# ET6801 register map
Vendor: ETMCU Inc.; File version: v0.0.1
CPU: CM7 r2p1, little endian, MPU, FPU, I-cache, D-cache, ITCM, DTCM, 4 interrupt priority bits
Registers are 32-bit, read-write, reset 0x0 unless marked. A register's access mark holds for its fields unless they carry their own. Offsets are from the block's base; [hi:lo] are bit positions; {n}, {i} and the like mark numbered series.

## AES — Provide an overview of the purpose and functionality of the peripheral: aes_cfg
Base 0x40205000
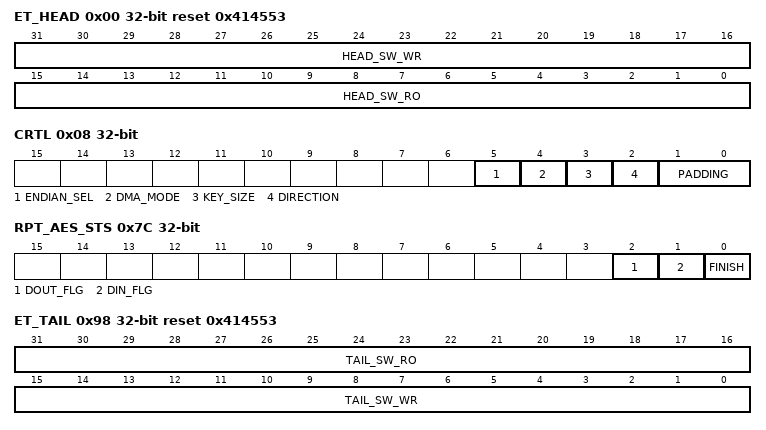
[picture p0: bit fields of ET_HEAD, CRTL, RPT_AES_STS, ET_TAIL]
0x00 ET_HEAD reset 0x414553
  [31:16] HEAD_SW_WR — 软件测试读写寄存器，硬件无访问
  [15:0] HEAD_SW_RO ro — 软件只读上报寄存器，硬件无访问,AES的ASICII 码表示
0x04 WORK
  [0] EN — AES模块使能控制信号。
0x08 CRTL
  [5] ENDIAN_SEL — 加解密数据，密钥，IV的大小端模式选择 1'b0:小端模式，默认； 1'b1:大端模式；
  [4] DMA_MODE — DMA搬运数据的模式 : 1'b0:FIFO模式，burst4 ,地址fix； 1'b1:寄存器模式, burst4 ,地址wrap；
  [3] KEY_SIZE — 密钥长度: 1'b0: 128bit密钥； 1'b1: 256bit密钥；
  [2] DIRECTION — AES 加解密模式配置: 1'b0: 加密模式； 1'b1: 解秘模式；
  [1:0] PADDING — 加密数据最后一个明文块的填充方式： 2'b00:no_padding，输入数据限制为16字节整数倍，不填充，默认； 2'b01: zeros_padding，缺少的字节填充8'h00； 2'b10: pkcs#7_padding，缺少的字节填充缺失的字节数;
0x0C WORK_KEY0
  [31:0] KEY0 — AES加解密密钥的[31:0]；
{0xC+4i} WORK_KEY{i} (i=1..7)
  [31:0] KEY{i} — AES加解密密钥的 [{32i+31}:{32i}]；
{0x2C+4i} WORK_IV{i} (i=0..3)
  [31:0] IV{i} — AES 初始向量的[{32i+31}:{32i}]；
0x3C DATA_SIZE0
  [31:0] SIZE0 — 配置加解密数据长度的[31:0]，与CFG_AES_DATA_SIZE1拼接，单位为byte
0x40 DATA_SIZE1
  [3:0] SIZE1 — 配置加解密数据长度的[35:32]，与CFG_AES_DATA_SIZE0拼接，单位为byte
0x44 WORK_MODE
  [1:0] MODE — AES 工作模式配置: 2'b00: ECB模式； 2'b01: CBC模式； 2'b10: CTR模式；
0x48 BLOCK_CNT
  [31:0] BLOCK_CNT — CTR计数器配置，主要用于CTR模式下，配置计数器的初始值，必须配置。
{0x4C+4i} DIN{i} (i=0..3)
  [31:0] DIN{i} — AES 搬运：DMA 寄存器模式，中断模式，轮询模式下输入数据的[{32i+31}:{32i}]；
0x5C DATA
  [31:0] DIN wo — AES DMA FIFO模式下输入数据；
0x60 DMA
  [1:0] EN — [1]bit位：DMA搬运数据输出AES使能控制信号; [0] bit位：DMA搬运数据进入AES使能控制信号； 1'b1: 打开; 1'b0: 关闭。
{0x64+4i} RESULT_DOUT{i} ro (i=0..3)
  [31:0] DOUT{i} — AES搬运：DMA 寄存器模式，中断模式，轮询模式下输出数据块的[{32i+31}:{32i}];
0x74 RESULT ro
  [31:0] DOUT — DMA FIFO模式下，burst4的固定地址寄存器；
0x78 RPT_AES_WORK ro
  [0] BUSY — AES 模块的工作状态上报： 1'b1: Busy; 1'b0: IDLE。
0x7C RPT_AES_STS
  [2] DOUT_FLG — AES 读出数据请求标志信号，软件写1清： 1'b1: 读出当前结果数据块数据; 1'b0: 不读出数据。
  [1] DIN_FLG — AES 输入数据请求标志信号，软件写1清： 1'b1: 写入下一个数据块; 1'b0: 不写入数据。
  [0] FINISH — AES 加解密事件结束状态上报，软件写1清： 1'b1: 事件结束; 1'b0: 事件未完成。
0x80 INT_EN
  [6:0] INT_EN — bit[6] : 非DMA工作场景下，产生的输出数据中断请求； bit[5] : 非DMA工作场景下，产生的输入数据中断请求； bit[4] : 事件未结束拉低使能中断； bit[3] : 事件结束中断； bit[2] : 初始向量缺失中断； bit[1] : 密钥缺失中断； bit[0] : 寄存器输出数据冲突中断； 'b0：取消中断使能； 'b1：打开中断使能;
0x84 INT_MASK
  [6:0] MASK — bit[6] : 非DMA工作场景下，产生的输出数据中断请求； bit[5] : 非DMA工作场景下，产生的输入数据中断请求； bit[4] : 事件未结束拉低使能中断； bit[3] : 事件结束中断； bit[2] : 初始向量缺失中断； bit[1] : 密钥缺失中断； bit[0] : 寄存器输出数据冲突中断； 'b0：取消屏蔽； 'b1：打开屏蔽;
0x88 INT_FORCE_IND
  [6:0] FORCE_IND — bit[6] : 非DMA工作场景下，产生的输出数据中断请求； bit[5] : 非DMA工作场景下，产生的输入数据中断请求； bit[4] : 事件未结束拉低使能中断； bit[3] : 事件结束中断； bit[2] : 初始向量缺失中断； bit[1] : 密钥缺失中断； bit[0] : 寄存器输出数据冲突中断； 'b0：不强制产生相应的测试中断； 'b1：强制产生相应的测试中断，硬件自动产生一个高脉冲，回读为0;
0x8C INT_CLR
  [6:0] INT_CLR — bit[6] : 非DMA工作场景下，产生的输出数据中断请求； bit[5] : 非DMA工作场景下，产生的输入数据中断请求； bit[4] : 事件未结束拉低使能中断； bit[3] : 事件结束中断； bit[2] : 初始向量缺失中断； bit[1] : 密钥缺失中断； bit[0] : 寄存器输出数据冲突中断； 'b0：不产生中断清零信号； 'b1：产生中断清零信号，硬件自动产生一个高脉冲，回读为0;
0x90 RPT_AES_INT_STATUS ro
  [6:0] INT_STATUS — bit[6] : 非DMA工作场景下，产生的输出数据中断请求； bit[5] : 非DMA工作场景下，产生的输入数据中断请求； bit[4] : 事件未结束拉低使能中断； bit[3] : 事件结束中断； bit[2] : 初始向量缺失中断； bit[1] : 密钥缺失中断； bit[0] : 寄存器输出数据冲突中断； 经中断屏蔽处理后的中断状态上报
0x94 RPT_AES_INT_RAW ro
  [6:0] INT_RAW — bit[6] : 非DMA工作场景下，产生的输出数据中断请求； bit[5] : 非DMA工作场景下，产生的输入数据中断请求； bit[4] : 事件未结束拉低使能中断； bit[3] : 事件结束中断； bit[2] : 初始向量缺失中断； bit[1] : 密钥缺失中断； bit[0] : 寄存器输出数据冲突中断； 未经中断屏蔽处理的中断状态上报
0x98 ET_TAIL reset 0x414553
  [31:16] TAIL_SW_RO ro — 软件只读硬件上报寄存器
  [15:0] TAIL_SW_WR — 软件测试读写寄存器，硬件无访问

## CRC — Provide an overview of the purpose and functionality of the peripheral: crc_cfg
Base 0x40206000
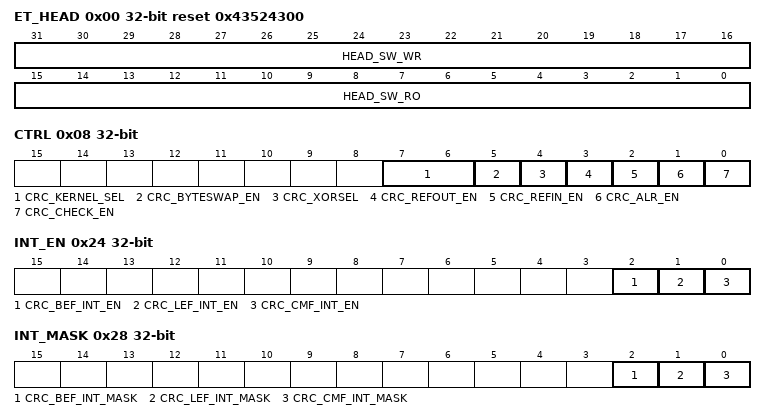
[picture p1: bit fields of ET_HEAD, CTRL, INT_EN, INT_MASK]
0x00 ET_HEAD reset 0x43524300
  [31:16] HEAD_SW_WR — 软件测试读写寄存器，硬件无访问
  [15:0] HEAD_SW_RO ro — 软件只读上报寄存器，硬件无访问，CRC的ASICII 码表示
0x04 MODULE_EN
  [0] CRC_EN — 软件控制该位确定模块是否使能 'b0: 模块不使能 'b1：模块使能
0x08 CTRL
  [7:6] CRC_KERNEL_SEL — 软件控制该位选择CRC内核 'h0:选择kernel0(CRC32) 'h1:选择kernel1(CRC16) 'h2-'h3:选择kernel2(CRC8)
  [5] CRC_BYTESWAP_EN — 软件控制IR输入寄存器的值是否按字节交换（针对CRC32和CRC16） 'b0:进行CRC计算之前不交换字节 'b1:进行CRC计算之前交换字节
  [4] CRC_XORSEL — 软件控制该位最终CRC计算结果的异或值 'b0:0x0000000 'b1:0xffffffff
  [3] CRC_REFOUT_EN — 软件控制最终输出数据是否按位反转 'b0:不使能按位反转 'b1:使能按按位反转
  [2] CRC_REFIN_EN — 软件控制输入数据是否按字节内反转 'b0:不使能按字节内反转 'b1:使能按字节内反转
  [1] CRC_ALR_EN — 软件控制该位使能crc 长度自动加载功能，使能该功能，将会自动重新加载上一次配置的长度值 'b0:不使能长度自动加载功能 'b1:使能长度自动加载功能
  [0] CRC_CHECK_EN — 软件控制该位使能crc check功能 'b0:不使能check功能 'b1:使能check功能
0x0C POLY
  [31:0] CRC_POLY — CRC多项式，CRC16时，有效多项式在高两个字节；CRC8时，有效多项式在高一个字节。
0x10 FIFO_TRHD reset 0x8
  [3:0] CRC_FIFO_TRHD — FIFO水线配置寄存器，默认为最大。
0x14 IR
  [31:0] CRC_IR — 输入数据（报文）寄存器 计算CRC32时，整个32bit有效；计算CRC16时，数据低16位有效；计算CRC8时，数据低8位有效
0x18 INI
  [31:0] CRC_INI — CRC计算初始值 计算CRC32时，整个32bit有效；计算CRC16时，数据低16位有效；计算CRC8时，数据低8位有效
0x1C CHECK
  [31:0] CRC_CHECK — 软件写入CHECK校验值，最终计算的CRC结果将会与写入期望的CHECK值进行比较，使用该功能前，需要使能该功能
0x20 LENGTH
  [15:0] CRC_LENGTH — 数据（报文）长度LENGTH寄存器，软件配置的长度以多项式的位数为单位长度
0x24 INT_EN
  [2] CRC_BEF_INT_EN — 总线错误中断使能寄存器，软件控制该位是否使能中断 'b0：使能中断 'b1：不使能中断
  [1] CRC_LEF_INT_EN — 长度错误中断使能寄存器，软件控制该位是否使能中断 'b0：使能中断 'b1：不使能中断
  [0] CRC_CMF_INT_EN — 匹配错误中断使能寄存器，软件控制该位是否使能中断 'b0：使能中断 'b1：不使能中断
0x28 INT_MASK
  [2] CRC_BEF_INT_MASK — 总线错误中断屏蔽寄存器，软件控制该位是否屏蔽中断 'b0：不屏蔽中断 'b1：屏蔽中断
  [1] CRC_LEF_INT_MASK — 长度错误中断屏蔽寄存器，软件控制该位是否屏蔽中断 'b0：不屏蔽中断 'b1：屏蔽中断
  [0] CRC_CMF_INT_MASK — 匹配错误中断屏蔽寄存器，软件控制该位是否屏蔽中断 'b0：不屏蔽中断 'b1：屏蔽中断
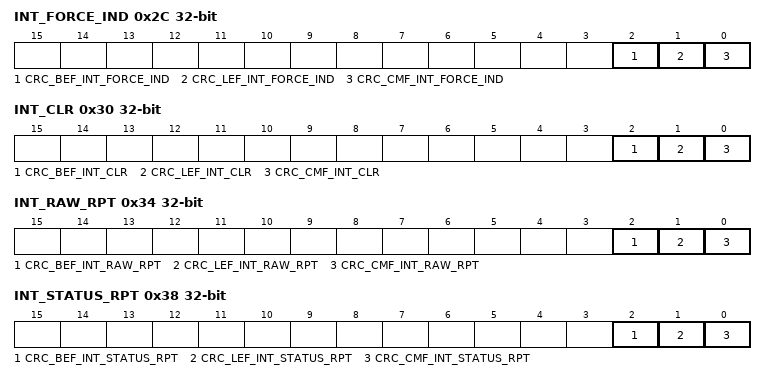
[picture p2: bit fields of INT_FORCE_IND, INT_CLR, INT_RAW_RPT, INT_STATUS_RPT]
0x2C INT_FORCE_IND
  [2] CRC_BEF_INT_FORCE_IND — 总线错误中断测试寄存器，软件控制该位是否测试中断 'b0:不测试中断脉冲 'b1:测试中断脉冲
  [1] CRC_LEF_INT_FORCE_IND — 长度错误中断测试寄存器，软件控制该位是否测试中断 'b0:不测试中断脉冲 'b1:测试中断脉冲
  [0] CRC_CMF_INT_FORCE_IND — 匹配错误中断测试寄存器，软件控制该位是否测试中断 'b0:不测试中断脉冲 'b1:测试中断脉冲
0x30 INT_CLR
  [2] CRC_BEF_INT_CLR — ch0 总线错误中断清除脉冲信号，软件控制该位是否清除脉冲信号 'b0：不清除中断脉冲信号 'b1：清除中断脉冲信号
  [1] CRC_LEF_INT_CLR — ch0 长度错误中断清除脉冲信号，软件控制该位是否清除脉冲信号 'b0：不清除中断脉冲信号 'b1：清除中断脉冲信号
  [0] CRC_CMF_INT_CLR — ch0 匹配错误中断清除脉冲信号，软件控制该位是否清除脉冲信号 'b0：不清除中断脉冲信号 'b1：清除中断脉冲信号
0x34 INT_RAW_RPT ro
  [2] CRC_BEF_INT_RAW_RPT — CRC总线错误中断标志（原始中断状态，未屏蔽） 'b1：产生中断 'b0: 未产生中断
  [1] CRC_LEF_INT_RAW_RPT — CRC长度错误中断（原始中断状态，未屏蔽） 'b1：产生中断 'b0: 未产生中断
  [0] CRC_CMF_INT_RAW_RPT — CRC匹配错误中断标志（原始中断状态，未屏蔽） 'b1：产生中断 'b0: 未产生中断
0x38 INT_STATUS_RPT ro
  [2] CRC_BEF_INT_STATUS_RPT — CRC总线错误中断标志（屏蔽后） 'b1：产生中断 'b0: 未产生中断
  [1] CRC_LEF_INT_STATUS_RPT — CRC长度错误中断（屏蔽后） 'b1：产生中断 'b0: 未产生中断
  [0] CRC_CMF_INT_STATUS_RPT — CRC匹配错误中断标志（屏蔽后） 'b1：产生中断 'b0: 未产生中断
0x3C RES ro
  [31:0] POST_CRC_CAL — 输出最终结果寄存器，当配置CRC16或CRC8时，仅低16位或者低8位有效
0x40 FIFO_OVF ro
  [0] CRC_FIFO_OVF_RPT — FIFO溢出告警寄存器，为高表示有溢出错误告警。
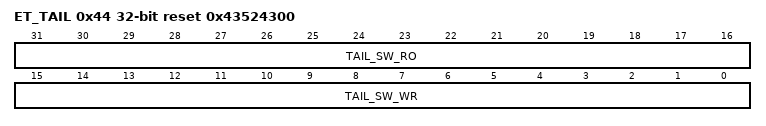
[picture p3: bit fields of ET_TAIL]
0x44 ET_TAIL reset 0x43524300
  [31:16] TAIL_SW_RO ro — 软件测试读写寄存器，硬件无访问
  [15:0] TAIL_SW_WR — 软件只读上报寄存器，硬件无访问，CRC的ASICII 码表示
